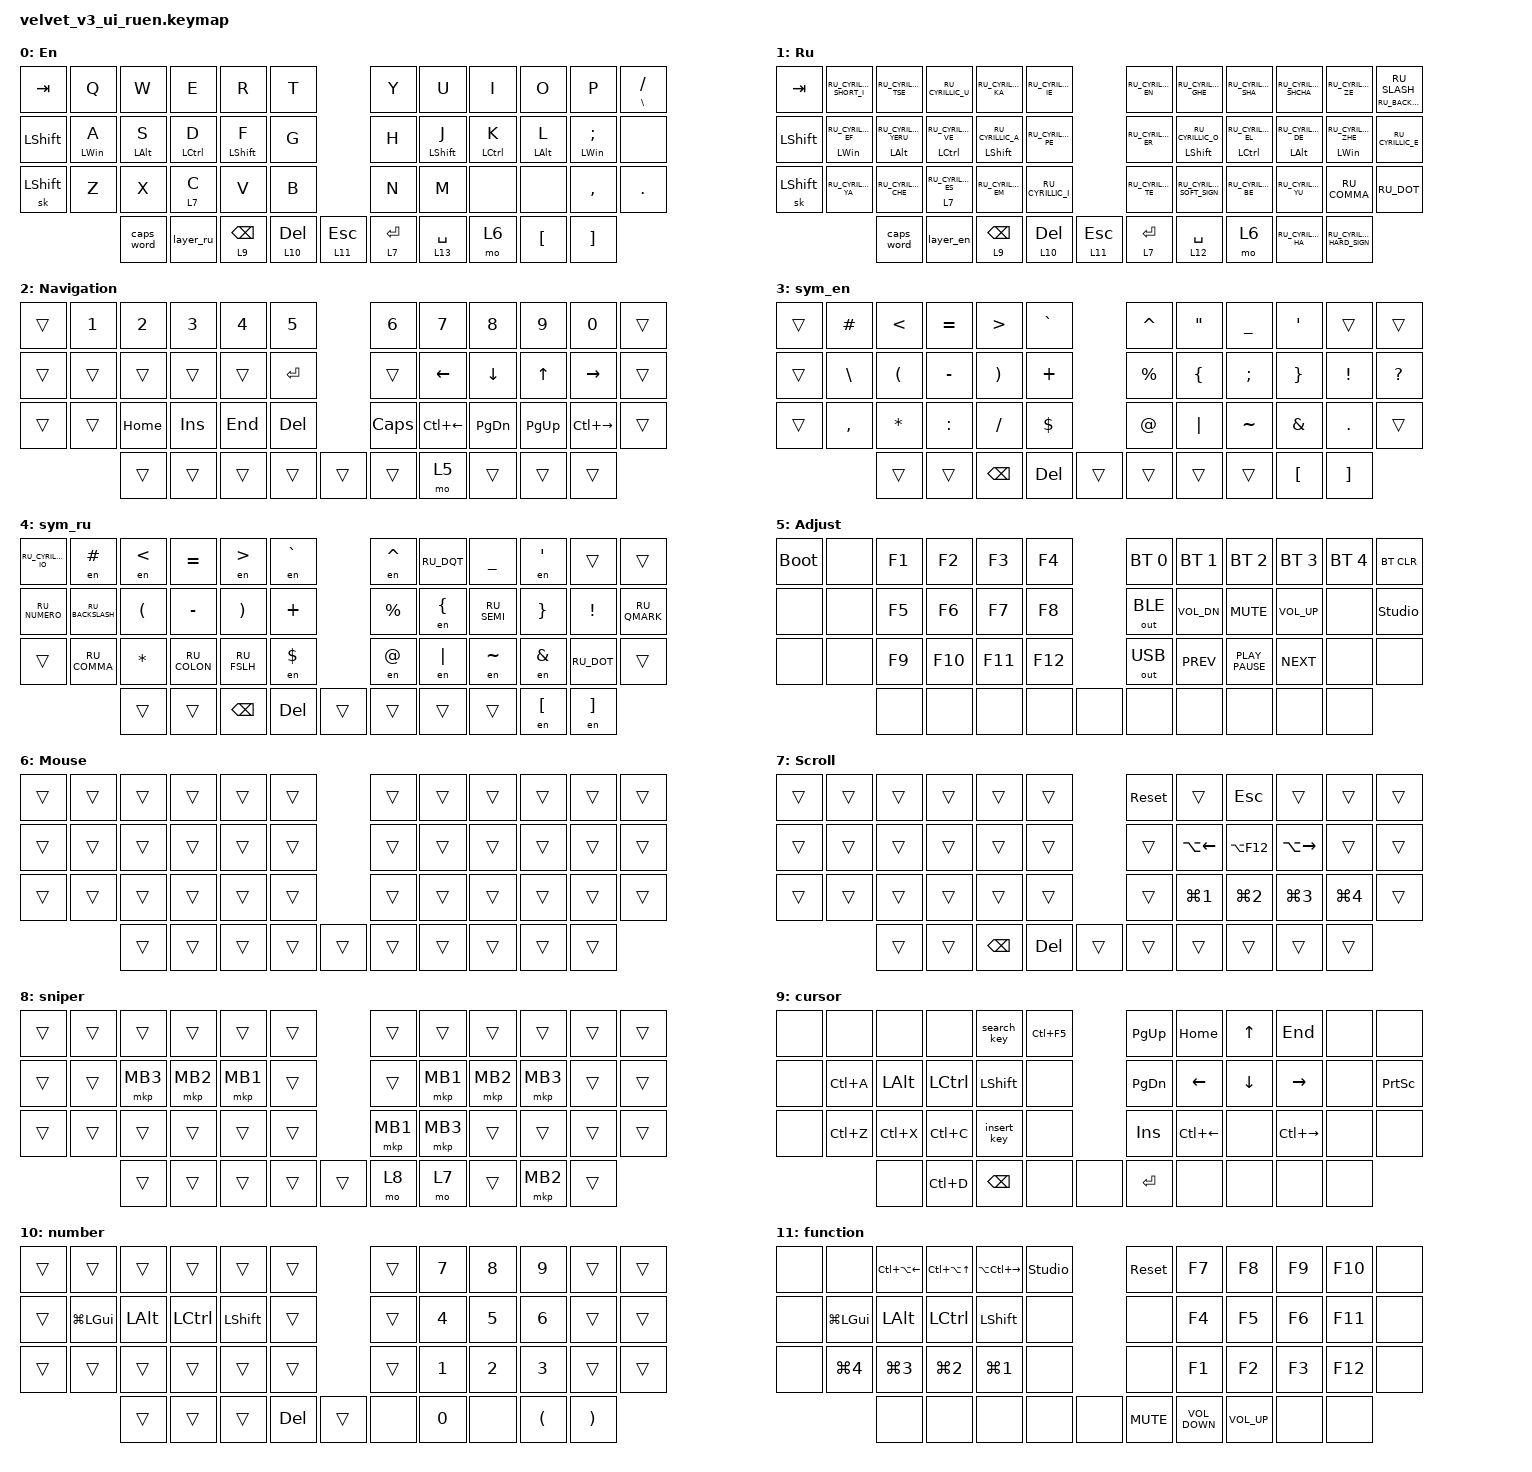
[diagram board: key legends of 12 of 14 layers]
#include "keys_ru.h"
#include <dt-bindings/zmk/input_transform.h>
#include <input/processors.dtsi>
#include <zephyr/dt-bindings/input/input-event-codes.h>
#include <behaviors.dtsi>
#include <dt-bindings/zmk/bt.h>
#include <dt-bindings/zmk/keys.h>
#include <dt-bindings/zmk/outputs.h>
#include <dt-bindings/zmk/pointing.h>

&mt {
    quick-tap-ms = <200>;
    require-prior-idle-ms = <125>;
    flavor = "tap-preferred";
};

/ {
    behaviors {
        cap_sen: cap_sen {
            compatible = "zmk,behavior-hold-tap";
            label = "CAP_SEN";
            bindings = <&mo>, <&mkp>;

            #binding-cells = <2>;
            tapping-term-ms = <150>;
            hold-while-undecided;
        };

        mouse_layer: mouse_layer {
            compatible = "zmk,behavior-sticky-key";
            label = "MOUSE_LAYER";
            bindings = <&mo>;
            #binding-cells = <1>;
            release-after-ms = <200>;
        };

        zip_auto_mouse: zip_auto_mouse {
            compatible = "zmk,input-processor-temp-layer";
            #input-processor-cells = <2>;
            require-prior-idle-ms = <800>;
            excluded-positions = <>;
        };

        hml: home_row_mod_left {
            compatible = "zmk,behavior-hold-tap";
            bindings = <&kp>, <&kp>;

            #binding-cells = <2>;
            tapping-term-ms = <280>;
            quick-tap-ms = <175>;
            require-prior-idle-ms = <150>;
            flavor = "balanced";
            hold-trigger-on-release;
            hold-trigger-key-positions = <41 42 43 45 44 18 30 31 6 7 8 9 10 11 18 19 20 21 22 23 30 31 32 33 34 35>;
        };

        hmr: home_row_mod_right {
            compatible = "zmk,behavior-hold-tap";
            bindings = <&kp>, <&kp>;

            #binding-cells = <2>;
            tapping-term-ms = <280>;
            quick-tap-ms = <175>;
            require-prior-idle-ms = <150>;
            flavor = "balanced";
            hold-trigger-on-release;
            hold-trigger-key-positions = <0 1 2 3 4 5 12 13 14 15 16 17 24 25 26 27 28 29 36 37 38 39 40>;
        };

        search_key: search_key {
            compatible = "zmk,behavior-tap-dance";
            label = "SEARCH_KEY";
            #binding-cells = <0>;
            bindings = <&kp LC(F)>, <&kp LC(LS(F))>;
        };

        cur_bcksp: cursor_backspase {
            compatible = "zmk,behavior-tap-dance";
            #binding-cells = <0>;
            bindings = <&lt 9 BACKSPACE>, <&kp BACKSPACE>;
        };

        num_del: num_delete {
            compatible = "zmk,behavior-tap-dance";
            #binding-cells = <0>;
            bindings = <&lt 10 DELETE>, <&kp DELETE>;
        };

        insert_key: insert_key {
            compatible = "zmk,behavior-tap-dance";
            label = "INSERT_KEY";
            #binding-cells = <0>;
            bindings = <&kp LC(V)>, <&kp LC(LS(V))>;
        };
    };

    combos {
        compatible = "zmk,combos";

        adj {
            bindings = <&mo 5>;
            key-positions = <39 40>;
        };

        scroll {
            bindings = <&mo 7>;
            key-positions = <41 42>;
        };

        mb1 {
            bindings = <&mkp MB1>;
            key-positions = <33 32>;
            layers = <0 1>;
        };

        mb2 {
            bindings = <&mkp MB2>;
            key-positions = <44 45>;
            layers = <0 1>;
        };

        mb3-right {
            bindings = <&mkp MB3>;
            key-positions = <33 31>;
            layers = <0 1>;
        };

        mb1-left {
            bindings = <&mkp MB1>;
            key-positions = <28 27>;
            layers = <0 1 6 12 13>;
        };

        mb2-left {
            bindings = <&mkp MB2>;
            key-positions = <26 27>;
            layers = <0 1 12 13 6>;
        };

        mb3-left {
            bindings = <&mkp MB3>;
            key-positions = <26 28>;
            layers = <0 1 12 13 6>;
        };
    };

    macros {
        to_ru: to_ru {
            compatible = "zmk,behavior-macro";
            #binding-cells = <0>;
            bindings = <&kp LS(LA(SPACE))>;
            label = "TO_RU";
            wait-ms = <0>;
            tap-ms = <30>;
        };

        to_en: to_en {
            compatible = "zmk,behavior-macro";
            #binding-cells = <0>;
            bindings = <&kp LS(LEFT_ALT)>;
            label = "TO_EN";
            wait-ms = <0>;
            tap-ms = <30>;
        };

        layer_en: layer_en {
            compatible = "zmk,behavior-macro";
            #binding-cells = <0>;
            bindings = <&to 0 &to_en>;
            label = "LAYER_EN";
            wait-ms = <0>;
            tap-ms = <30>;
        };

        layer_ru: layer_ru {
            compatible = "zmk,behavior-macro";
            #binding-cells = <0>;
            bindings = <&to 1 &to_ru>;
            label = "LAYER_RU";
            tap-ms = <30>;
            wait-ms = <0>;
        };

        en: en {
            compatible = "zmk,behavior-macro-one-param";
            #binding-cells = <1>;
            bindings =
                <&to_en>,
                <&macro_press>,
                <&macro_param_1to1 &kp MACRO_PLACEHOLDER>,
                <&macro_pause_for_release>,
                <&macro_release>,
                <&macro_param_1to1 &kp MACRO_PLACEHOLDER>,
                <&macro_tap>,
                <&to_ru>;

            label = "EN";
            wait-ms = <0>;
            tap-ms = <30>;
        };
    };

    keymap {
        compatible = "zmk,keymap";

        en {
            bindings = <
&kp TAB         &kp Q            &kp W            &kp E         &kp R              &kp T                                     &kp Y         &kp U              &kp I         &kp O            &kp P               &mt BACKSLASH SLASH
&kp LEFT_SHIFT  &hml LEFT_WIN A  &hml LEFT_ALT S  &hml LCTRL D  &hml LEFT_SHIFT F  &kp G                                     &kp H         &hmr LEFT_SHIFT J  &hmr LCTRL K  &hmr LEFT_ALT L  &hmr LEFT_WIN SEMI  &none
&sk LEFT_SHIFT  &kp Z            &kp X            &lt 7 C       &kp V              &kp B                                     &kp N         &kp M              &none         &none            &kp COMMA           &kp DOT
                                 &caps_word       &layer_ru     &lt 9 BACKSPACE    &lt 10 DEL  &lt 11 ESCAPE    &lt 7 ENTER  &lt 13 SPACE  &mo 6              &kp LBKT      &kp RBKT
            >;

            display-name = "En";
        };

        ru {
            display-name = "Ru";
            bindings = <
&kp TAB         &kp RU_CYRILLIC_SHORT_I       &kp RU_CYRILLIC_TSE             &kp RU_CYRILLIC_U          &kp RU_CYRILLIC_KA            &kp RU_CYRILLIC_IE                             &kp RU_CYRILLIC_EN  &kp RU_CYRILLIC_GHE            &kp RU_CYRILLIC_SHA        &kp RU_CYRILLIC_SHCHA         &kp RU_CYRILLIC_ZE             &mt RU_BACKSLASH RU_SLASH
&kp LEFT_SHIFT  &hml LEFT_WIN RU_CYRILLIC_EF  &hml LEFT_ALT RU_CYRILLIC_YERU  &hml LCTRL RU_CYRILLIC_VE  &mt LEFT_SHIFT RU_CYRILLIC_A  &kp RU_CYRILLIC_PE                             &kp RU_CYRILLIC_ER  &hmr LEFT_SHIFT RU_CYRILLIC_O  &hmr LCTRL RU_CYRILLIC_EL  &hmr LEFT_ALT RU_CYRILLIC_DE  &hmr LEFT_WIN RU_CYRILLIC_ZHE  &kp RU_CYRILLIC_E
&sk LEFT_SHIFT  &kp RU_CYRILLIC_YA            &kp RU_CYRILLIC_CHE             &lt 7 RU_CYRILLIC_ES       &kp RU_CYRILLIC_EM            &kp RU_CYRILLIC_I                              &kp RU_CYRILLIC_TE  &kp RU_CYRILLIC_SOFT_SIGN      &kp RU_CYRILLIC_BE         &kp RU_CYRILLIC_YU            &kp RU_COMMA                   &kp RU_DOT
                                              &caps_word                      &layer_en                  &lt 9 BACKSPACE               &lt 10 DEL          &lt 11 ESC    &lt 7 ENTER  &lt 12 SPACE        &mo 6                          &kp RU_CYRILLIC_HA         &kp RU_CYRILLIC_HARD_SIGN
            >;
        };

        nav {
            bindings = <
&trans  &kp N1  &kp N2    &kp N3   &kp N4   &kp N5                     &kp N6    &kp N7        &kp N8         &kp N9       &kp N0         &trans
&trans  &trans  &trans    &trans   &trans   &kp RET                    &trans    &kp LEFT      &kp DOWN       &kp UP       &kp RIGHT      &trans
&trans  &trans  &kp HOME  &kp INS  &kp END  &kp DEL                    &kp CLCK  &kp LC(LEFT)  &kp PAGE_DOWN  &kp PAGE_UP  &kp LC(RIGHT)  &trans
                &trans    &trans   &trans   &trans   &trans    &trans  &mo 5     &trans        &trans         &trans
            >;

            display-name = "Navigation";
        };

        sym_en {
            bindings = <
&trans  &kp HASH   &kp LT    &kp EQUAL  &kp GT         &kp GRAVE                     &kp CARET  &kp DQT   &kp UNDER  &kp SQT   &trans    &trans
&trans  &kp BSLH   &kp LPAR  &kp MINUS  &kp RPAR       &kp PLUS                      &kp PRCNT  &kp LBRC  &kp SEMI   &kp RBRC  &kp EXCL  &kp QUESTION
&trans  &kp COMMA  &kp STAR  &kp COLON  &kp FSLH       &kp DLLR                      &kp AT     &kp PIPE  &kp TILDE  &kp AMPS  &kp DOT   &trans
                   &trans    &trans     &kp BACKSPACE  &kp DELETE  &trans    &trans  &trans     &trans    &kp LBKT   &kp RBKT
            >;

            display-name = "sym_en";
        };

        sym_ru {
            display-name = "sym_ru";
            bindings = <
&kp RU_CYRILLIC_IO  &en HASH          &en LT    &kp EQUAL     &en GT         &en GRAVE                     &en CARET  &kp RU_DQT  &kp UNDER    &en SQT   &trans      &trans
&kp RU_NUMERO       &kp RU_BACKSLASH  &kp LPAR  &kp MINUS     &kp RPAR       &kp PLUS                      &kp PRCNT  &en LBRC    &kp RU_SEMI  &kp RBRC  &kp EXCL    &kp RU_QMARK
&trans              &kp RU_COMMA      &kp STAR  &kp RU_COLON  &kp RU_FSLH    &en DLLR                      &en AT     &en PIPE    &en TILDE    &en AMPS  &kp RU_DOT  &trans
                                      &trans    &trans        &kp BACKSPACE  &kp DELETE  &trans    &trans  &trans     &trans      &en LBKT     &en RBKT
            >;
        };

        adj {
            bindings = <
&bootloader  &none  &kp F1  &kp F2   &kp F3   &kp F4                   &bt BT_SEL 0  &bt BT_SEL 1  &bt BT_SEL 2      &bt BT_SEL 3  &bt BT_SEL 4  &bt BT_CLR
&none        &none  &kp F5  &kp F6   &kp F7   &kp F8                   &out OUT_BLE  &kp C_VOL_DN  &kp K_MUTE        &kp C_VOL_UP  &none         &studio_unlock
&none        &none  &kp F9  &kp F10  &kp F11  &kp F12                  &out OUT_USB  &kp K_PREV    &kp K_PLAY_PAUSE  &kp K_NEXT    &none         &none
                    &none   &none    &none    &none    &none    &none  &none         &none         &none             &none
            >;

            display-name = "Adjust";
        };

        mouse {
            bindings = <
&trans  &trans  &trans  &trans  &trans  &trans                    &trans  &trans  &trans  &trans  &trans  &trans
&trans  &trans  &trans  &trans  &trans  &trans                    &trans  &trans  &trans  &trans  &trans  &trans
&trans  &trans  &trans  &trans  &trans  &trans                    &trans  &trans  &trans  &trans  &trans  &trans
                &trans  &trans  &trans  &trans  &trans    &trans  &trans  &trans  &trans  &trans
            >;

            display-name = "Mouse";
        };

        scroll {
            bindings = <
&trans  &trans  &trans  &trans  &trans         &trans                        &sys_reset  &trans            &kp ESC           &trans            &trans            &trans
&trans  &trans  &trans  &trans  &trans         &trans                        &trans      &kp LA(LEFT)      &kp LA(F12)       &kp LA(RIGHT)     &trans            &trans
&trans  &trans  &trans  &trans  &trans         &trans                        &trans      &kp LG(NUMBER_1)  &kp LG(NUMBER_2)  &kp LG(NUMBER_3)  &kp LG(NUMBER_4)  &trans
                &trans  &trans  &kp BACKSPACE  &kp DELETE  &trans    &trans  &trans      &trans            &trans            &trans
            >;

            display-name = "Scroll";
        };

        sniper {
            bindings = <
&trans  &trans  &trans    &trans    &trans    &trans                   &trans    &trans    &trans    &trans    &trans  &trans
&trans  &trans  &mkp MB3  &mkp MB2  &mkp MB1  &trans                   &trans    &mkp MB1  &mkp MB2  &mkp MB3  &trans  &trans
&trans  &trans  &trans    &trans    &trans    &trans                   &mkp MB1  &mkp MB3  &trans    &trans    &trans  &trans
                &trans    &trans    &trans    &trans  &trans    &mo 8  &mo 7     &trans    &mkp MB2  &trans
            >;
        };

        cursor {
            bindings = <
&none  &none      &none      &none      &search_key    &kp LC(F5)                    &kp PAGE_UP    &kp HOME            &kp UP    &kp END              &none  &none
&none  &kp LC(A)  &kp LALT   &kp LCTRL  &kp LSHFT      &none                         &kp PAGE_DOWN  &kp LEFT            &kp DOWN  &kp RIGHT            &none  &kp PRINTSCREEN
&none  &kp LC(Z)  &kp LC(X)  &kp LC(C)  &insert_key    &none                         &kp INS        &kp LC(LEFT_ARROW)  &none     &kp LC(RIGHT_ARROW)  &none  &none
                  &none      &kp LC(D)  &kp BACKSPACE  &none       &none    &kp RET  &none          &none               &none     &none
            >;
        };

        number {
            bindings = <
&trans  &trans        &trans    &trans     &trans     &trans                       &trans        &kp N7  &kp N8                &kp N9                 &trans  &trans
&trans  &kp LG(LGUI)  &kp LALT  &kp LCTRL  &kp LSHFT  &trans                       &trans        &kp N4  &kp N5                &kp N6                 &trans  &trans
&trans  &trans        &trans    &trans     &trans     &trans                       &trans        &kp N1  &kp N2                &kp N3                 &trans  &trans
                      &trans    &trans     &trans     &kp DELETE  &trans    &none  &kp NUMBER_0  &none   &kp LEFT_PARENTHESIS  &kp RIGHT_PARENTHESIS
            >;
        };

        function {
            bindings = <
&none  &none         &kp LC(LA(LEFT_ARROW))  &kp LC(LA(UP))  &kp LA(LC(RIGHT_ARROW))  &studio_unlock                       &sys_reset         &kp F7           &kp F8  &kp F9  &kp F10  &none
&none  &kp LG(LGUI)  &kp LALT                &kp LCTRL       &kp LSHFT                &none                                &none              &kp F4           &kp F5  &kp F6  &kp F11  &none
&none  &kp LG(N4)    &kp LG(N3)              &kp LG(N2)      &kp LG(N1)               &none                                &none              &kp F1           &kp F2  &kp F3  &kp F12  &none
                     &none                   &none           &none                    &none           &none    &kp K_MUTE  &kp C_VOLUME_DOWN  &kp C_VOLUME_UP  &none   &none
            >;
        };

        sunaku_sym_ru {
            bindings = <
&en TILDE    &en LEFT_BRACE  &kp LPAR   &kp RPAR        &en RIGHT_BRACE   &en DOLLAR                         &none   &kp RU_DQT  &en SQT      &none     &none     &trans
&kp RU_EXCL  &en CARET       &kp EQUAL  &kp UNDERSCORE  &en HASH          &kp STAR                           &en AT  &kp LSHFT   &kp LCTRL    &kp LALT  &kp LGUI  &kp RU_QMARK
&en GRAVE    &en LESS_THAN   &en PIPE   &kp MINUS       &en GREATER_THAN  &kp RU_FSLH                        &none   &none       &kp RU_SEMI  &none     &trans    &trans
                             &en AMPS   &kp PLUS        &kp RU_BACKSLASH  &kp RU_COLON  &kp PRCNT    &trans  &trans  &trans      &en LBKT     &en RBKT
            >;
        };

        sunaku_sym_en {
            bindings = <
&kp TILDE  &kp LEFT_BRACE  &kp LEFT_PARENTHESIS  &kp RIGHT_PARENTHESIS  &kp RIGHT_BRACE   &kp DOLLAR                       &none   &kp DQT    &kp SQT    &none     &none     &trans
&kp EXCL   &kp CARET       &kp EQUAL             &kp UNDERSCORE         &kp HASH          &kp STAR                         &kp AT  &kp LSHFT  &kp LCTRL  &kp LALT  &kp LGUI  &kp QMARK
&kp GRAVE  &kp LESS_THAN   &kp PIPE              &kp MINUS              &kp GREATER_THAN  &kp FSLH                         &none   &none      &kp SEMI   &none     &trans    &trans
                           &kp AMPS              &kp PLUS               &kp BSLH          &kp COLON   &kp PRCNT    &trans  &trans  &trans     &kp LBKT   &kp RBKT
            >;
        };
    };
};

&trackball { cpi = <1000>; };

&trackball_listener {
    input-processors = <&zip_auto_mouse 6 500>, <&zip_xy_scaler 9 20>;

    scroller {
        layers = <7>;
        input-processors =
            <&zip_xy_transform INPUT_TRANSFORM_Y_INVERT>,
            <&zip_xy_scaler 1 32>,
            <&zip_xy_to_scroll_mapper>;
    };

    sniper {
        layers = <8>;
        input-processors = <&zip_xy_scaler 1 4>;
    };
};
